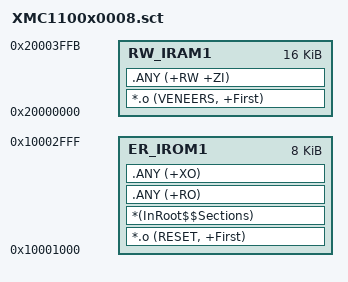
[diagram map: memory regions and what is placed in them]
; *************************************************************
; *** Scatter-Loading Description File generated by uVision ***
; *************************************************************
;*********************************************************************************************************************
;* @file     XMC1100x0008.sct
;* @brief    Scatter-Loading Description File for Infineon XMC1100 8K Flash Devices
;* @version  V1.0
;* @date     09 Nov 2018
;*
;* @cond
;*********************************************************************************************************************
;* Copyright (c) 2015-2019, Infineon Technologies AG
;* All rights reserved.                        
;*                                             
;* Redistribution and use in source and binary forms, with or without modification,are permitted provided that the 
;* following conditions are met:   
;*                                                                              
;* Redistributions of source code must retain the above copyright notice, this list of conditions and the following 
;* disclaimer.                        
;* 
;* Redistributions in binary form must reproduce the above copyright notice, this list of conditions and the following 
;* disclaimer in the documentation and/or other materials provided with the distribution.                       
;* 
;* Neither the name of the copyright holders nor the names of its contributors may be used to endorse or promote 
;* products derived from this software without specific prior written permission.                                           
;*                                                                              
;* THIS SOFTWARE IS PROVIDED BY THE COPYRIGHT HOLDERS AND CONTRIBUTORS "AS IS" AND ANY EXPRESS OR IMPLIED WARRANTIES, 
;* INCLUDING, BUT NOT LIMITED TO, THE IMPLIED WARRANTIES OF MERCHANTABILITY AND FITNESS FOR A PARTICULAR PURPOSE ARE  
;* DISCLAIMED. IN NO EVENT SHALL THE COPYRIGHT HOLDER OR CONTRIBUTORS BE LIABLE  FOR ANY DIRECT, INDIRECT, INCIDENTAL, 
;* SPECIAL, EXEMPLARY, OR CONSEQUENTIAL DAMAGES (INCLUDING, BUT NOT LIMITED TO, PROCUREMENT OF SUBSTITUTE GOODS OR  
;* SERVICES; LOSS OF USE, DATA, OR PROFITS; OR BUSINESS INTERRUPTION) HOWEVER CAUSED AND ON ANY THEORY OF LIABILITY, 
;* WHETHER IN CONTRACT, STRICT LIABILITY,OR TORT (INCLUDING NEGLIGENCE OR OTHERWISE) ARISING IN ANY WAY OUT OF THE USE 
;* OF THIS SOFTWARE, EVEN IF ADVISED OF THE POSSIBILITY OF SUCH DAMAGE.                                                  
;*                                                                              
;* To improve the quality of the software, users are encouraged to share modifications, enhancements or bug fixes with 
;* Infineon Technologies AG dave@infineon.com).                                                          
;*********************************************************************************************************************
;*
;**************************** Change history ********************************
;* V1.1, Nov, 09, 2018 JFT:Initial version
;*
;* @endcond 
;*

LR_IROM1 0x10001000 0x00002000  {    ; load region size_region
  ER_IROM1 0x10001000 0x00002000  {  ; load address = execution address
   *.o (RESET, +First)
   *(InRoot$$Sections)
   .ANY (+RO)
   .ANY (+XO)
  }
  RW_IRAM1 0x20000000 0x00003FFC  {  ; RW data
   *.o (VENEERS, +First)
   .ANY (+RW +ZI)
  }
}

